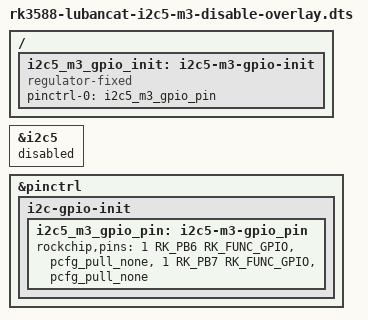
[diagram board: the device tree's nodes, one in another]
/dts-v1/;
/plugin/;

#include <dt-bindings/gpio/gpio.h>
#include <dt-bindings/pinctrl/rockchip.h>

/ {
	fragment@0 {
		target = <&i2c5>;

		__overlay__ {
			status = "disabled";
		};
	};

	fragment@1 {
		target-path = "/";
		__overlay__ {
			i2c5_m3_gpio_init: i2c5-m3-gpio-init {
				compatible = "regulator-fixed";
				pinctrl-names = "default";
				pinctrl-0 = <&i2c5_m3_gpio_pin>;
			};
		};
	};

	fragment@3 {
		target = <&pinctrl>;
		__overlay__ {
			i2c-gpio-init {
				i2c5_m3_gpio_pin: i2c5-m3-gpio_pin {
					rockchip,pins =
						<1 RK_PB6 RK_FUNC_GPIO &pcfg_pull_none>,
						<1 RK_PB7 RK_FUNC_GPIO &pcfg_pull_none>;
				};
			};
		};
	};
};
